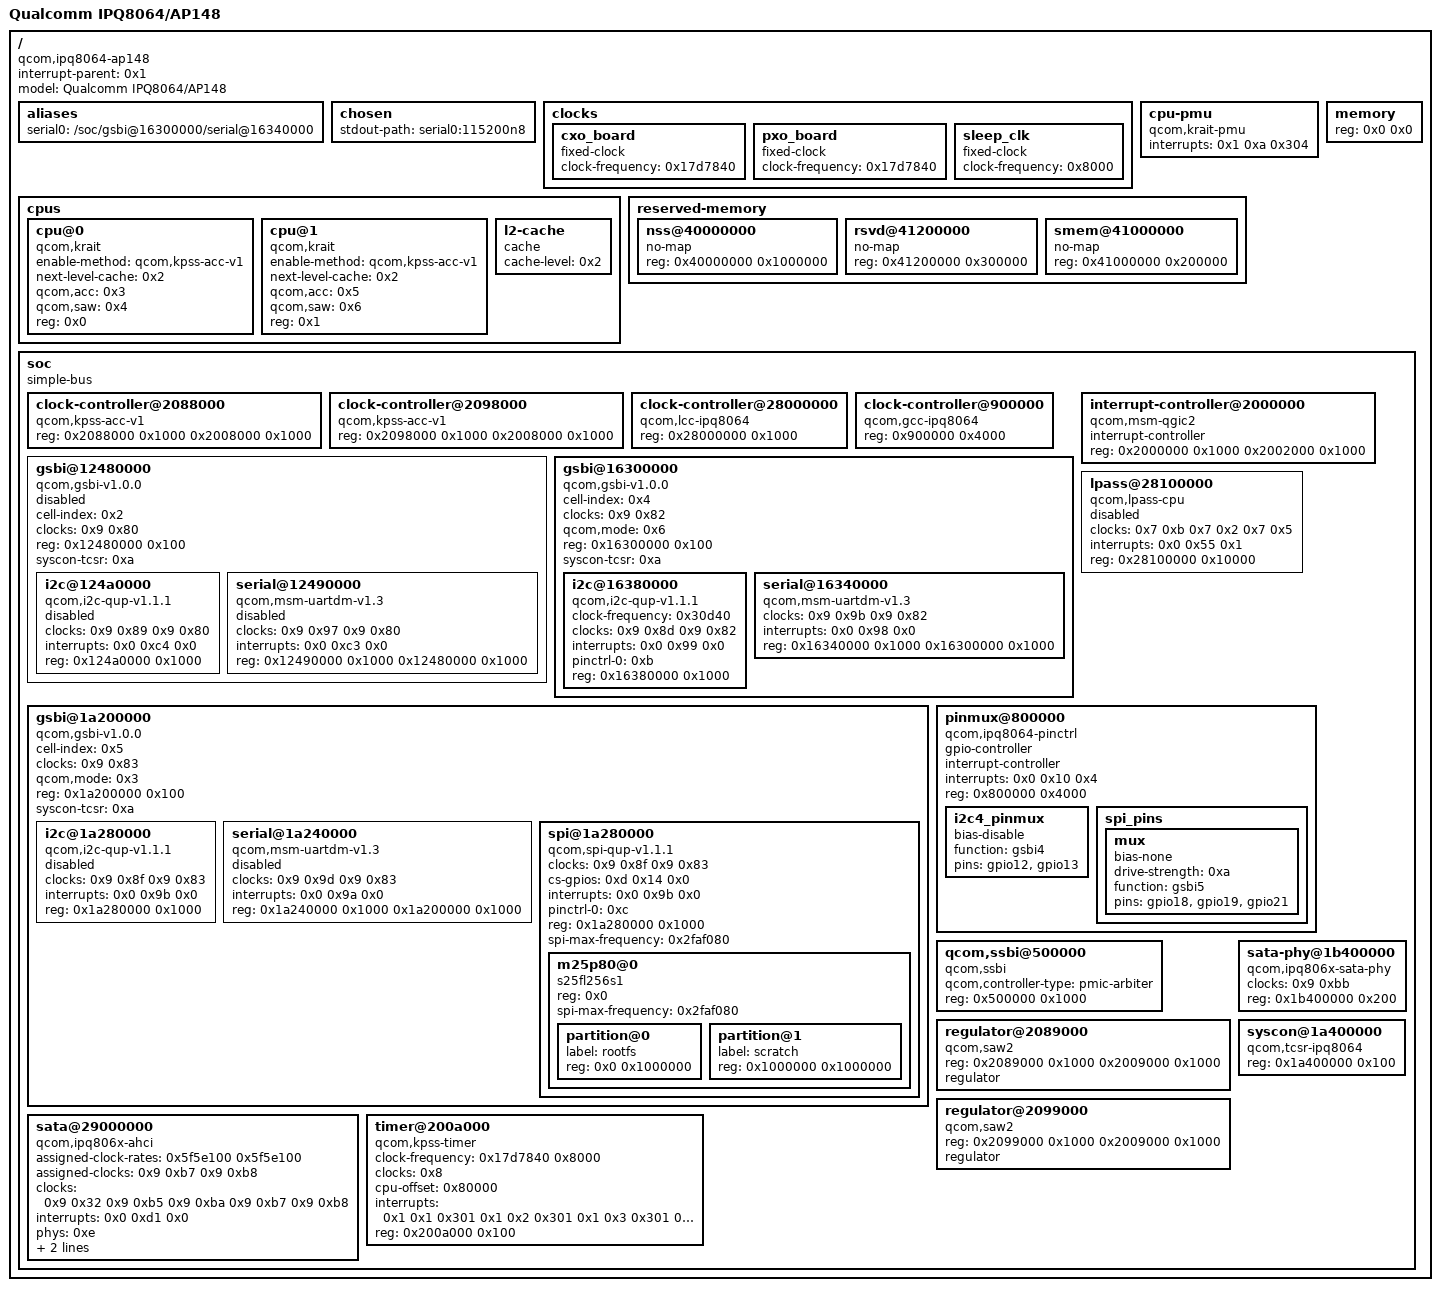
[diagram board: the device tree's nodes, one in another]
/dts-v1/;

/ {
	#address-cells = <0x1>;
	#size-cells = <0x1>;
	compatible = "qcom,ipq8064-ap148", "qcom,ipq8064";
	interrupt-parent = <0x1>;
	model = "Qualcomm IPQ8064/AP148";

	__symbols__ {
		L2 = "/cpus/l2-cache";
		acc0 = "/soc/clock-controller@2088000";
		acc1 = "/soc/clock-controller@2098000";
		flash = "/soc/gsbi@1a200000/spi@1a280000/m25p80@0";
		gcc = "/soc/clock-controller@900000";
		gsbi2 = "/soc/gsbi@12480000";
		gsbi4 = "/soc/gsbi@16300000";
		gsbi4_serial = "/soc/gsbi@16300000/serial@16340000";
		gsbi5 = "/soc/gsbi@1a200000";
		i2c4 = "/soc/gsbi@16300000/i2c@16380000";
		i2c4_pins = "/soc/pinmux@800000/i2c4_pinmux";
		intc = "/soc/interrupt-controller@2000000";
		lcc = "/soc/clock-controller@28000000";
		qcom_pinmux = "/soc/pinmux@800000";
		sata_phy = "/soc/sata-phy@1b400000";
		saw0 = "/soc/regulator@2089000";
		saw1 = "/soc/regulator@2099000";
		sleep_clk = "/clocks/sleep_clk";
		soc = "/soc";
		spi4 = "/soc/gsbi@1a200000/spi@1a280000";
		spi_pins = "/soc/pinmux@800000/spi_pins";
		tcsr = "/soc/syscon@1a400000";
	};

	aliases {
		serial0 = "/soc/gsbi@16300000/serial@16340000";
	};

	chosen {
		stdout-path = "serial0:115200n8";
	};

	clocks {

		cxo_board {
			#clock-cells = <0x0>;
			clock-frequency = <0x17d7840>;
			compatible = "fixed-clock";
		};

		pxo_board {
			#clock-cells = <0x0>;
			clock-frequency = <0x17d7840>;
			compatible = "fixed-clock";
		};

		sleep_clk {
			#clock-cells = <0x0>;
			clock-frequency = <0x8000>;
			compatible = "fixed-clock";
			phandle = <0x8>;
		};
	};

	cpu-pmu {
		compatible = "qcom,krait-pmu";
		interrupts = <0x1 0xa 0x304>;
	};

	cpus {
		#address-cells = <0x1>;
		#size-cells = <0x0>;

		cpu@0 {
			compatible = "qcom,krait";
			device_type = "cpu";
			enable-method = "qcom,kpss-acc-v1";
			next-level-cache = <0x2>;
			qcom,acc = <0x3>;
			qcom,saw = <0x4>;
			reg = <0x0>;
		};

		cpu@1 {
			compatible = "qcom,krait";
			device_type = "cpu";
			enable-method = "qcom,kpss-acc-v1";
			next-level-cache = <0x2>;
			qcom,acc = <0x5>;
			qcom,saw = <0x6>;
			reg = <0x1>;
		};

		l2-cache {
			cache-level = <0x2>;
			compatible = "cache";
			phandle = <0x2>;
		};
	};

	memory {
		device_type = "memory";
		reg = <0x0 0x0>;
	};

	reserved-memory {
		#address-cells = <0x1>;
		#size-cells = <0x1>;
		ranges;

		nss@40000000 {
			no-map;
			reg = <0x40000000 0x1000000>;
		};

		rsvd@41200000 {
			no-map;
			reg = <0x41200000 0x300000>;
		};

		smem@41000000 {
			no-map;
			reg = <0x41000000 0x200000>;
		};
	};

	soc {
		#address-cells = <0x1>;
		#size-cells = <0x1>;
		compatible = "simple-bus";
		phandle = <0xf>;
		ranges;

		clock-controller@2088000 {
			compatible = "qcom,kpss-acc-v1";
			phandle = <0x3>;
			reg = <0x2088000 0x1000 0x2008000 0x1000>;
		};

		clock-controller@2098000 {
			compatible = "qcom,kpss-acc-v1";
			phandle = <0x5>;
			reg = <0x2098000 0x1000 0x2008000 0x1000>;
		};

		clock-controller@28000000 {
			#clock-cells = <0x1>;
			#reset-cells = <0x1>;
			compatible = "qcom,lcc-ipq8064";
			phandle = <0x7>;
			reg = <0x28000000 0x1000>;
		};

		clock-controller@900000 {
			#clock-cells = <0x1>;
			#reset-cells = <0x1>;
			compatible = "qcom,gcc-ipq8064";
			phandle = <0x9>;
			reg = <0x900000 0x4000>;
		};

		gsbi@12480000 {
			#address-cells = <0x1>;
			#size-cells = <0x1>;
			cell-index = <0x2>;
			clock-names = "iface";
			clocks = <0x9 0x80>;
			compatible = "qcom,gsbi-v1.0.0";
			phandle = <0x10>;
			ranges;
			reg = <0x12480000 0x100>;
			status = "disabled";
			syscon-tcsr = <0xa>;

			i2c@124a0000 {
				#address-cells = <0x1>;
				#size-cells = <0x0>;
				clock-names = "core", "iface";
				clocks = <0x9 0x89 0x9 0x80>;
				compatible = "qcom,i2c-qup-v1.1.1";
				interrupts = <0x0 0xc4 0x0>;
				reg = <0x124a0000 0x1000>;
				status = "disabled";
			};

			serial@12490000 {
				clock-names = "core", "iface";
				clocks = <0x9 0x97 0x9 0x80>;
				compatible = "qcom,msm-uartdm-v1.3", "qcom,msm-uartdm";
				interrupts = <0x0 0xc3 0x0>;
				reg = <0x12490000 0x1000 0x12480000 0x1000>;
				status = "disabled";
			};
		};

		gsbi@16300000 {
			#address-cells = <0x1>;
			#size-cells = <0x1>;
			cell-index = <0x4>;
			clock-names = "iface";
			clocks = <0x9 0x82>;
			compatible = "qcom,gsbi-v1.0.0";
			phandle = <0x11>;
			qcom,mode = <0x6>;
			ranges;
			reg = <0x16300000 0x100>;
			status = "ok";
			syscon-tcsr = <0xa>;

			i2c@16380000 {
				#address-cells = <0x1>;
				#size-cells = <0x0>;
				clock-frequency = <0x30d40>;
				clock-names = "core", "iface";
				clocks = <0x9 0x8d 0x9 0x82>;
				compatible = "qcom,i2c-qup-v1.1.1";
				interrupts = <0x0 0x99 0x0>;
				phandle = <0x13>;
				pinctrl-0 = <0xb>;
				pinctrl-names = "default";
				reg = <0x16380000 0x1000>;
				status = "ok";
			};

			serial@16340000 {
				clock-names = "core", "iface";
				clocks = <0x9 0x9b 0x9 0x82>;
				compatible = "qcom,msm-uartdm-v1.3", "qcom,msm-uartdm";
				interrupts = <0x0 0x98 0x0>;
				phandle = <0x12>;
				reg = <0x16340000 0x1000 0x16300000 0x1000>;
				status = "ok";
			};
		};

		gsbi@1a200000 {
			#address-cells = <0x1>;
			#size-cells = <0x1>;
			cell-index = <0x5>;
			clock-names = "iface";
			clocks = <0x9 0x83>;
			compatible = "qcom,gsbi-v1.0.0";
			phandle = <0x14>;
			qcom,mode = <0x3>;
			ranges;
			reg = <0x1a200000 0x100>;
			status = "ok";
			syscon-tcsr = <0xa>;

			i2c@1a280000 {
				#address-cells = <0x1>;
				#size-cells = <0x0>;
				clock-names = "core", "iface";
				clocks = <0x9 0x8f 0x9 0x83>;
				compatible = "qcom,i2c-qup-v1.1.1";
				interrupts = <0x0 0x9b 0x0>;
				reg = <0x1a280000 0x1000>;
				status = "disabled";
			};

			serial@1a240000 {
				clock-names = "core", "iface";
				clocks = <0x9 0x9d 0x9 0x83>;
				compatible = "qcom,msm-uartdm-v1.3", "qcom,msm-uartdm";
				interrupts = <0x0 0x9a 0x0>;
				reg = <0x1a240000 0x1000 0x1a200000 0x1000>;
				status = "disabled";
			};

			spi@1a280000 {
				#address-cells = <0x1>;
				#size-cells = <0x0>;
				clock-names = "core", "iface";
				clocks = <0x9 0x8f 0x9 0x83>;
				compatible = "qcom,spi-qup-v1.1.1";
				cs-gpios = <0xd 0x14 0x0>;
				interrupts = <0x0 0x9b 0x0>;
				phandle = <0x15>;
				pinctrl-0 = <0xc>;
				pinctrl-names = "default";
				reg = <0x1a280000 0x1000>;
				spi-max-frequency = <0x2faf080>;
				status = "ok";

				m25p80@0 {
					#address-cells = <0x1>;
					#size-cells = <0x1>;
					compatible = "s25fl256s1";
					phandle = <0x16>;
					reg = <0x0>;
					spi-max-frequency = <0x2faf080>;

					partition@0 {
						label = "rootfs";
						reg = <0x0 0x1000000>;
					};

					partition@1 {
						label = "scratch";
						reg = <0x1000000 0x1000000>;
					};
				};
			};
		};

		interrupt-controller@2000000 {
			#interrupt-cells = <0x3>;
			compatible = "qcom,msm-qgic2";
			interrupt-controller;
			phandle = <0x1>;
			reg = <0x2000000 0x1000 0x2002000 0x1000>;
		};

		lpass@28100000 {
			clock-names = "ahbix-clk", "mi2s-osr-clk", "mi2s-bit-clk";
			clocks = <0x7 0xb 0x7 0x2 0x7 0x5>;
			compatible = "qcom,lpass-cpu";
			interrupt-names = "lpass-irq-lpaif";
			interrupts = <0x0 0x55 0x1>;
			reg = <0x28100000 0x10000>;
			reg-names = "lpass-lpaif";
			status = "disabled";
		};

		pinmux@800000 {
			#gpio-cells = <0x2>;
			#interrupt-cells = <0x2>;
			compatible = "qcom,ipq8064-pinctrl";
			gpio-controller;
			interrupt-controller;
			interrupts = <0x0 0x10 0x4>;
			phandle = <0xd>;
			reg = <0x800000 0x4000>;

			i2c4_pinmux {
				bias-disable;
				function = "gsbi4";
				phandle = <0xb>;
				pins = "gpio12", "gpio13";
			};

			spi_pins {
				phandle = <0xc>;

				mux {
					bias-none;
					drive-strength = <0xa>;
					function = "gsbi5";
					pins = "gpio18", "gpio19", "gpio21";
				};
			};
		};

		qcom,ssbi@500000 {
			compatible = "qcom,ssbi";
			qcom,controller-type = "pmic-arbiter";
			reg = <0x500000 0x1000>;
		};

		regulator@2089000 {
			compatible = "qcom,saw2";
			phandle = <0x4>;
			reg = <0x2089000 0x1000 0x2009000 0x1000>;
			regulator;
		};

		regulator@2099000 {
			compatible = "qcom,saw2";
			phandle = <0x6>;
			reg = <0x2099000 0x1000 0x2009000 0x1000>;
			regulator;
		};

		sata-phy@1b400000 {
			#phy-cells = <0x0>;
			clock-names = "cfg";
			clocks = <0x9 0xbb>;
			compatible = "qcom,ipq806x-sata-phy";
			phandle = <0xe>;
			reg = <0x1b400000 0x200>;
			status = "ok";
		};

		sata@29000000 {
			assigned-clock-rates = <0x5f5e100 0x5f5e100>;
			assigned-clocks = <0x9 0xb7 0x9 0xb8>;
			clock-names = "slave_face", "iface", "core", "rxoob", "pmalive";
			clocks = <0x9 0x32 0x9 0xb5 0x9 0xba 0x9 0xb7 0x9 0xb8>;
			compatible = "qcom,ipq806x-ahci", "generic-ahci";
			interrupts = <0x0 0xd1 0x0>;
			phy-names = "sata-phy";
			phys = <0xe>;
			ports-implemented = <0x1>;
			reg = <0x29000000 0x180>;
			status = "ok";
		};

		syscon@1a400000 {
			compatible = "qcom,tcsr-ipq8064", "syscon";
			phandle = <0xa>;
			reg = <0x1a400000 0x100>;
		};

		timer@200a000 {
			clock-frequency = <0x17d7840 0x8000>;
			clock-names = "sleep";
			clocks = <0x8>;
			compatible = "qcom,kpss-timer", "qcom,kpss-wdt-ipq8064", "qcom,msm-timer";
			cpu-offset = <0x80000>;
			interrupts = <0x1 0x1 0x301 0x1 0x2 0x301 0x1 0x3 0x301 0x1 0x4 0x301 0x1 0x5 0x301>;
			reg = <0x200a000 0x100>;
		};
	};
};
